AUTOSAR XML (schema 4-0-3)
standard types defined: Boolean, UInt32
package /AUTOSAR_Platform/DataConstrs
  range DC_Boolean: raw 0..1
package /PATAC/MSM/ComponentTypes
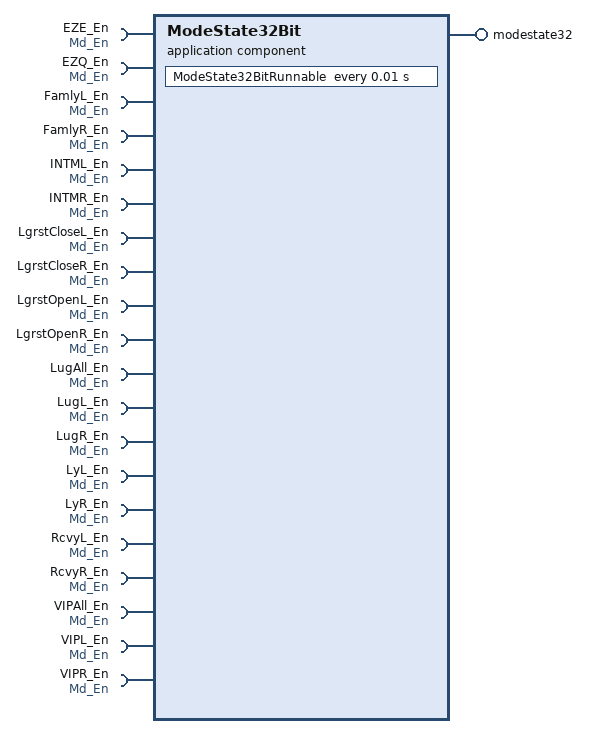
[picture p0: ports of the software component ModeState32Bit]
  application sw component type ModeState32Bit
    provide port modestate32: nonqueued-sender-com-spec{data-element=modestate32/Val, init-value=0}, provided-interface=modestate32
    20 x require port, all with nonqueued-receiver-com-spec{data-element=Md_En/Val, filter=data-filter-type=ALWAYS, init-value=0}, required-interface=Md_En:
      EZE_En
      EZQ_En
      FamlyL_En
      FamlyR_En
      INTML_En
      INTMR_En
      LgrstCloseL_En
      LgrstCloseR_En
      LgrstOpenL_En
      LgrstOpenR_En
      LugAll_En
      LugL_En
      LugR_En
      LyL_En
      LyR_En
      RcvyL_En
      RcvyR_En
      VIPAll_En
      VIPL_En
      VIPR_En
    behavior ModeState32Bit_InternalBehavior
      timing event TMT_ModeState32BitRunnable: start-on-event=ModeState32BitRunnable, period=0.01
      runnable ModeState32BitRunnable
        data-receive-point-by-arguments:
          20 x access:
            REC_EZE_En_Val: accessed-variable=EZE_En.Val
            REC_EZQ_En_Val: accessed-variable=EZQ_En.Val
            REC_FamlyL_En_Val: accessed-variable=FamlyL_En.Val
            REC_FamlyR_En_Val: accessed-variable=FamlyR_En.Val
            REC_INTML_En_Val: accessed-variable=INTML_En.Val
            REC_INTMR_En_Val: accessed-variable=INTMR_En.Val
            REC_LgrstCloseL_En_Val: accessed-variable=LgrstCloseL_En.Val
            REC_LgrstCloseR_En_Val: accessed-variable=LgrstCloseR_En.Val
            REC_LgrstOpenL_En_Val: accessed-variable=LgrstOpenL_En.Val
            REC_LgrstOpenR_En_Val: accessed-variable=LgrstOpenR_En.Val
            REC_LugAll_En_Val: accessed-variable=LugAll_En.Val
            REC_LugL_En_Val: accessed-variable=LugL_En.Val
            REC_LugR_En_Val: accessed-variable=LugR_En.Val
            REC_LyL_En_Val: accessed-variable=LyL_En.Val
            REC_LyR_En_Val: accessed-variable=LyR_En.Val
            REC_RcvyL_En_Val: accessed-variable=RcvyL_En.Val
            REC_RcvyR_En_Val: accessed-variable=RcvyR_En.Val
            REC_VIPAll_En_Val: accessed-variable=VIPAll_En.Val
            REC_VIPL_En_Val: accessed-variable=VIPL_En.Val
            REC_VIPR_En_Val: accessed-variable=VIPR_En.Val
        data-send-points:
          access SEND_modestate32_Val: accessed-variable=modestate32.Val
  swc implementation ModeState32Bit_Implementation: behavior=ModeState32Bit_InternalBehavior
    code-descriptors:
      code Default: artifact-descriptors=autosar-engineering-object={short-label=Default, category=SWSRC}
package /PATAC/MSM/ModeAdjust/PortInterface
  sender receiver interface Md_En: invalidation-policy{data-element=Md_En/Val, handle-invalid=DONT-INVALIDATE}
    data Val: type=Boolean
  sender receiver interface modestate32: invalidation-policy{data-element=modestate32/Val, handle-invalid=DONT-INVALIDATE}
    data Val: type=UInt32
